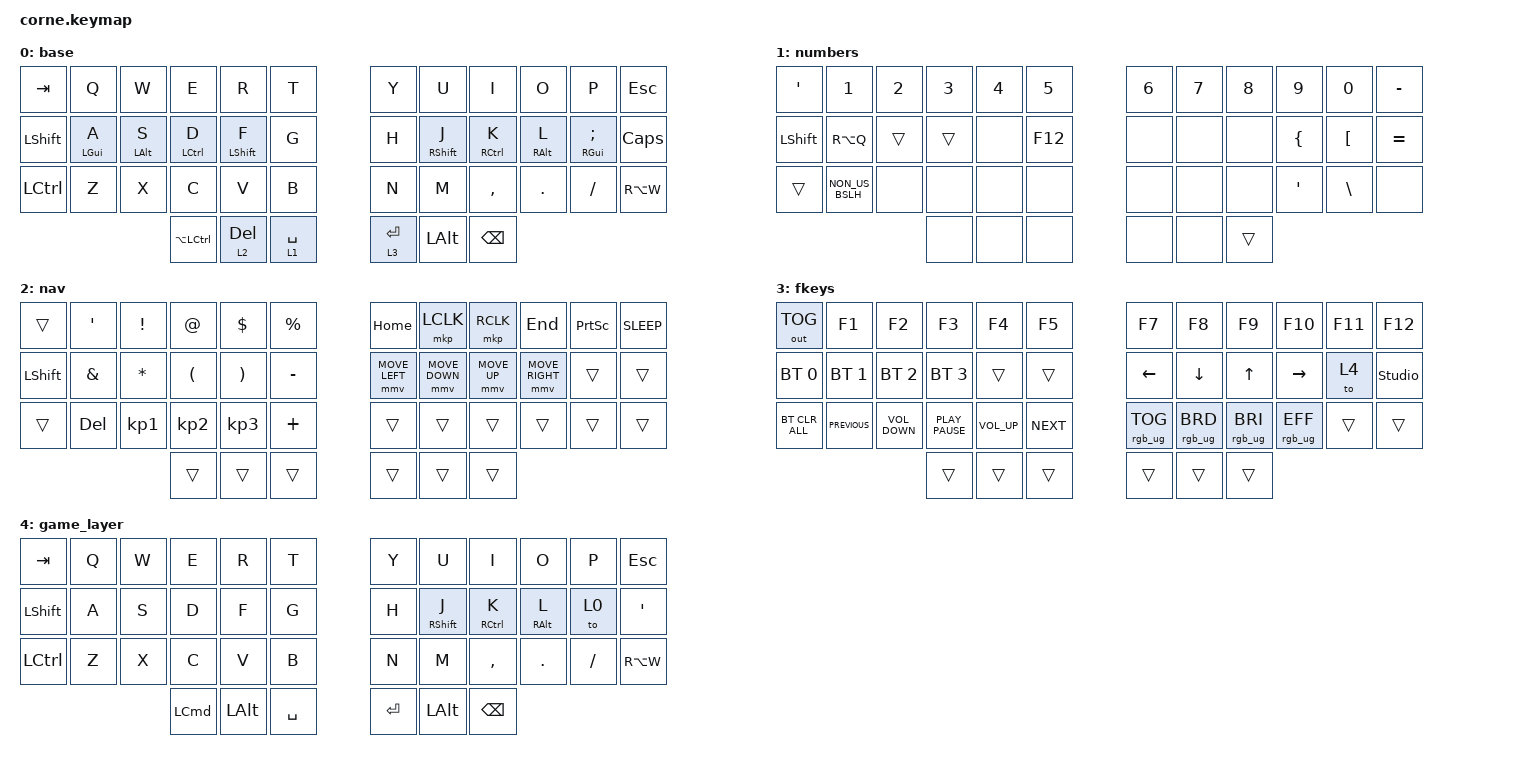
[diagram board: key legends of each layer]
/*
 * Copyright (c) 2020 The ZMK Contributors
 *
 * SPDX-License-Identifier: MIT
 */

#include "zmk-helpers/key-labels/36.h"                                      // Source key-labels.
#include <behaviors.dtsi>
#include <dt-bindings/zmk/bt.h>
#include <dt-bindings/zmk/keys.h>
#include <dt-bindings/zmk/outputs.h>
#include <dt-bindings/zmk/pointing.h>
#include <dt-bindings/zmk/rgb.h>

#define KEYS_L LT0 LT1 LT2 LT3 LT4 LM0 LM1 LM2 LM3 LM4 LB0 LB1 LB2 LB3 LB4  // Left-hand keys.
#define KEYS_R RT0 RT1 RT2 RT3 RT4 RM0 RM1 RM2 RM3 RM4 RB0 RB1 RB2 RB3 RB4  // Right-hand keys.
#define THUMBS LH2 LH1 LH0 RH0 RH1 RH2

/ {
    macros {
        rgblayer1: rgblayer {
            compatible = "zmk,behavior-macro-two-param";
            #binding-cells = <2>;
            bindings =
                <&macro_press>,
                <&macro_param_1to1 &macro_param_2to2 &lt MACRO_PLACEHOLDER MACRO_PLACEHOLDER>,
                <&macro_tap>,
                <&rgb_ug RGB_COLOR_HSB(0,100,48)>,
                <&macro_pause_for_release>,
                <&macro_release>,
                <&macro_param_1to2 &rgb_ug RGB_COLOR_HSB_CMD MACRO_PLACEHOLDER>;

            label = "RGBLAYER";
        };
    };

    behaviors {
        rgb_ug: rgb_ug {
            compatible = "zmk,behavior-rgb-underglow";
            #binding-cells = <2>;
        };

        hml: home_row_mod_left {
            compatible = "zmk,behavior-hold-tap";
            #binding-cells = <2>;
            flavor = "balanced";
            require-prior-idle-ms = <150>;
            tapping-term-ms = <280>;
            quick-tap-ms = <175>;
            bindings = <&kp>, <&kp>;

            hold-trigger-key-positions = <KEYS_R THUMBS>; // List of keys on the right side of the keyboard
            hold-trigger-on-release;
        };

        hmr: home_row_mod_right {
            compatible = "zmk,behavior-hold-tap";
            #binding-cells = <2>;
            flavor = "balanced";
            require-prior-idle-ms = <150>;
            tapping-term-ms = <280>;
            quick-tap-ms = <175>;
            bindings = <&kp>, <&kp>;

            hold-trigger-key-positions = <KEYS_L THUMBS>; // List of keys on the left side of the keyboard
            hold-trigger-on-release;
        };
    };

    layer_indicator {
        compatible = "zmk,layer-indicator";
        layer-colors = <
            RGB_COLOR_HSV(0, 0, 0)      // Default layer (off)
            RGB_COLOR_HSV(0, 100, 100)  // Lower layer (red)
            RGB_COLOR_HSV(120, 100, 50) // Raise layer (green)
            RGB_COLOR_HSV(240, 100, 50) // Layer 3 (blue)
        >;
    };

    keymap {
        compatible = "zmk,keymap";

        base {
            bindings = <
&kp TAB           &kp Q            &kp W            &kp E                &kp R              &kp T        &kp Y      &kp U               &kp I                 &kp O             &kp P                     &kp ESCAPE
&kp LEFT_SHIFT    &hml LEFT_GUI A  &hml LEFT_ALT S  &hml LEFT_CONTROL D  &hml LEFT_SHIFT F  &kp G        &kp H      &hml RIGHT_SHIFT J  &hml RIGHT_CONTROL K  &hml RIGHT_ALT L  &hml RIGHT_GUI SEMICOLON  &kp CLCK
&kp LEFT_CONTROL  &kp Z            &kp X            &kp C                &kp V              &kp B        &kp N      &kp M               &kp COMMA             &kp DOT           &kp FSLH                  &kp RA(W)
                                                    &kp LA(LCTRL)        &lt 2 DEL          &lt 1 SPACE  &lt 3 RET  &kp LEFT_ALT        &kp BACKSPACE
            >;
        };

        numbers {
            bindings = <
&kp SQT         &kp N1           &kp N2  &kp N3  &kp N4  &kp N5   &kp N6  &kp N7  &kp N8  &kp N9          &kp N0            &kp MINUS
&kp LEFT_SHIFT  &kp RA(Q)        &trans  &trans  &none   &kp F12  &none   &none   &none   &kp LEFT_BRACE  &kp LEFT_BRACKET  &kp EQUAL
&trans          &kp NON_US_BSLH  &none   &none   &none   &none    &none   &none   &none   &kp APOS        &kp BACKSLASH     &none
                                         &none   &none   &none    &none   &none   &trans
            >;
        };

        nav {
            bindings = <
&trans          &kp APOS       &kp EXCLAMATION  &kp AT_SIGN           &kp DOLLAR             &kp PERCENT  &kp HOME        &mkp LCLK       &mkp RCLK     &kp END          &kp PRINTSCREEN  &kp C_SLEEP
&kp LEFT_SHIFT  &kp AMPERSAND  &kp ASTERISK     &kp LEFT_PARENTHESIS  &kp RIGHT_PARENTHESIS  &kp MINUS    &mmv MOVE_LEFT  &mmv MOVE_DOWN  &mmv MOVE_UP  &mmv MOVE_RIGHT  &trans           &trans
&trans          &kp DELETE     &kp KP_NUMBER_1  &kp KP_NUMBER_2       &kp KP_NUMBER_3        &kp PLUS     &trans          &trans          &trans        &trans           &trans           &trans
                                                &trans                &trans                 &trans       &trans          &trans          &trans
            >;
        };

        fkeys {
            bindings = <
&out OUT_TOG    &kp F1          &kp F2             &kp F3            &kp F4           &kp F5      &kp F7           &kp F8           &kp F9           &kp F10          &kp F11  &kp F12
&bt BT_SEL 0    &bt BT_SEL 1    &bt BT_SEL 2       &bt BT_SEL 3      &trans           &trans      &kp LEFT         &kp DOWN         &kp UP_ARROW     &kp RIGHT        &to 4    &studio_unlock
&bt BT_CLR_ALL  &kp C_PREVIOUS  &kp C_VOLUME_DOWN  &kp K_PLAY_PAUSE  &kp C_VOLUME_UP  &kp C_NEXT  &rgb_ug RGB_TOG  &rgb_ug RGB_BRD  &rgb_ug RGB_BRI  &rgb_ug RGB_EFF  &trans   &trans
                                                   &trans            &trans           &trans      &trans           &trans           &trans
            >;
        };

        game_layer {
            bindings = <
&kp TAB           &kp Q  &kp W  &kp E             &kp R         &kp T      &kp Y      &kp U               &kp I                 &kp O             &kp P     &kp ESCAPE
&kp LEFT_SHIFT    &kp A  &kp S  &kp D             &kp F         &kp G      &kp H      &hml RIGHT_SHIFT J  &hml RIGHT_CONTROL K  &hml RIGHT_ALT L  &to 0     &kp SQT
&kp LEFT_CONTROL  &kp Z  &kp X  &kp C             &kp V         &kp B      &kp N      &kp M               &kp COMMA             &kp DOT           &kp FSLH  &kp RA(W)
                                &kp LEFT_COMMAND  &kp LEFT_ALT  &kp SPACE  &kp ENTER  &kp LEFT_ALT        &kp BACKSPACE
            >;
        };
    };
};
